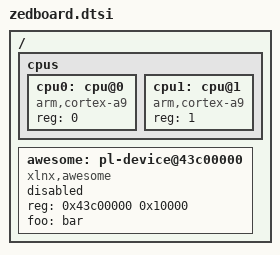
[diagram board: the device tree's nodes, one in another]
/ {
	#address-cells = <1>;
	#size-cells = <1>;

	cpus {
		#address-cells = <1>;
		#size-cells = <0>;

		cpu0: cpu@0 {
			compatible = "arm,cortex-a9";
			device_type = "cpu";
			reg = <0>;
		};

		cpu1: cpu@1 {
			compatible = "arm,cortex-a9";
			device_type = "cpu";
			reg = <1>;
		};
	};

	awesome: pl-device@43c00000 {
		compatible = "xlnx,awesome";
		reg = <0x43c00000 0x10000>;
		status = "disabled";
		#address-cells = <1>;
		#size-cells = <1>;
		foo = "bar";
	};
};
